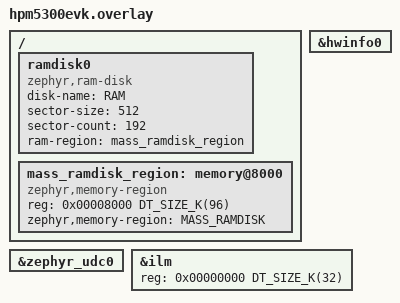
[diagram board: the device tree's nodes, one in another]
/*
* Copyright 2026 HPMicro
* SPDX-License-Identifier: Apache-2.0
*/

/ {
	ramdisk0 {
		compatible = "zephyr,ram-disk";
		disk-name = "RAM";
		sector-size = <512>;
		sector-count = <192>;
	};
};

&zephyr_udc0 {
	status = "okay";
};

&hwinfo0 {
	status = "okay";
};

&ilm {
	reg = <0x00000000 DT_SIZE_K(32)>;
};

/ {
	mass_ramdisk_region: memory@8000 {
		compatible = "zephyr,memory-region";
		reg = <0x00008000 DT_SIZE_K(96)>;
		zephyr,memory-region = "MASS_RAMDISK";
	};

	ramdisk0 {
		ram-region = <&mass_ramdisk_region>;
	};
};
